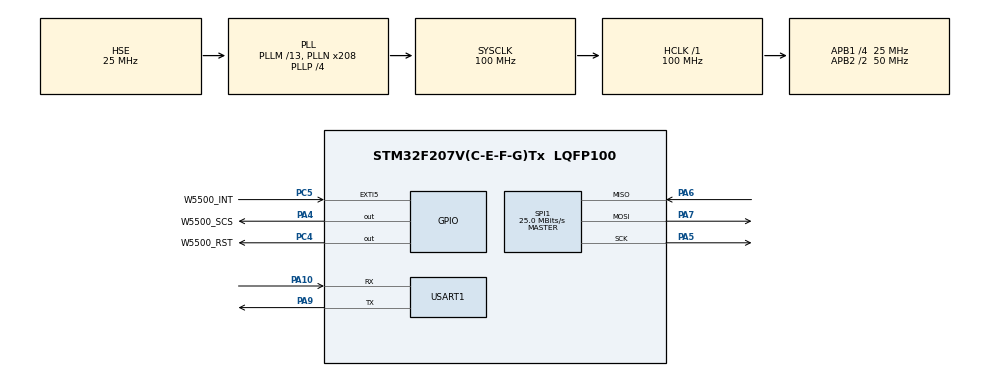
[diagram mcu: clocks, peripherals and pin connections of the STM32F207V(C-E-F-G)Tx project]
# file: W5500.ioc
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Mcu.Family=STM32F2
Mcu.Name=STM32F207V(C-E-F-G)Tx
Mcu.Package=LQFP100
NVIC.EXTI9_5_IRQn=true\:4\:0\:true\:true\:true\:1\:true
NVIC.PriorityGroup=NVIC_PRIORITYGROUP_4
PA10.Mode=Asynchronous
PA10.Signal=USART1_RX
PA13.Mode=Serial_Wire
PA13.Signal=SYS_JTMS-SWDIO
PA14.Mode=Serial_Wire
PA14.Signal=SYS_JTCK-SWCLK
PA4.GPIO_Label=W5500_SCS
PA4.Signal=GPIO_Output
PA5.Mode=Full_Duplex_Master
PA5.Signal=SPI1_SCK
PA6.Mode=Full_Duplex_Master
PA6.Signal=SPI1_MISO
PA7.Mode=Full_Duplex_Master
PA7.Signal=SPI1_MOSI
PA9.Mode=Asynchronous
PA9.Signal=USART1_TX
PC4.GPIO_Label=W5500_RST
PC4.Signal=GPIO_Output
PC5.GPIO_Label=W5500_INT
PC5.Signal=GPXTI5
PH0-OSC_IN.Mode=HSE-External-Oscillator
PH0-OSC_IN.Signal=RCC_OSC_IN
PH1-OSC_OUT.Mode=HSE-External-Oscillator
PH1-OSC_OUT.Signal=RCC_OSC_OUT
ProjectManager.HeapSize=0x200
ProjectManager.StackSize=0x400
ProjectManager.TargetToolchain=MDK-ARM V5
RCC.48MHZClocksFreq_Value=100000000
RCC.AHBFreq_Value=100000000
RCC.APB1CLKDivider=RCC_HCLK_DIV4
RCC.APB1Freq_Value=25000000
RCC.APB1TimFreq_Value=50000000
RCC.APB2CLKDivider=RCC_HCLK_DIV2
RCC.APB2Freq_Value=50000000
RCC.APB2TimFreq_Value=100000000
RCC.CortexFreq_Value=100000000
RCC.HCLKFreq_Value=100000000
RCC.HSE_VALUE=25000000
RCC.HSI_VALUE=16000000
RCC.LSE_VALUE=32768
RCC.PLLM=13
RCC.PLLN=208
RCC.PLLP=RCC_PLLP_DIV4
RCC.PLLSourceVirtual=RCC_PLLSOURCE_HSE
RCC.SYSCLKFreq_VALUE=100000000
RCC.SYSCLKSource=RCC_SYSCLKSOURCE_PLLCLK
RCC.VCOOutputFreq_Value=400000000
SPI1.BaudRatePrescaler=SPI_BAUDRATEPRESCALER_2
SPI1.CalculateBaudRate=25.0 MBits/s
SPI1.Direction=SPI_DIRECTION_2LINES
SPI1.Mode=SPI_MODE_MASTER
SPI1.VirtualType=VM_MASTER
USART1.VirtualMode=VM_ASYNC
board=W5500

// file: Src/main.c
/**
  ******************************************************************************
  * File Name          : main.c
  * Description        : Main program body
  ******************************************************************************
  ** This notice applies to any and all portions of this file
  * that are not between comment pairs USER CODE BEGIN and
  * USER CODE END. Other portions of this file, whether
  * inserted by the user or by software development tools
  * are owned by their respective copyright owners.
  *
  * COPYRIGHT(c) 2018 STMicroelectronics
  *
  * Redistribution and use in source and binary forms, with or without modification,
  * are permitted provided that the following conditions are met:
  *   1. Redistributions of source code must retain the above copyright notice,
  *      this list of conditions and the following disclaimer.
  *   2. Redistributions in binary form must reproduce the above copyright notice,
  *      this list of conditions and the following disclaimer in the documentation
  *      and/or other materials provided with the distribution.
  *   3. Neither the name of STMicroelectronics nor the names of its contributors
  *      may be used to endorse or promote products derived from this software
  *      without specific prior written permission.
  *
  * THIS SOFTWARE IS PROVIDED BY THE COPYRIGHT HOLDERS AND CONTRIBUTORS "AS IS"
  * AND ANY EXPRESS OR IMPLIED WARRANTIES, INCLUDING, BUT NOT LIMITED TO, THE
  * IMPLIED WARRANTIES OF MERCHANTABILITY AND FITNESS FOR A PARTICULAR PURPOSE ARE
  * DISCLAIMED. IN NO EVENT SHALL THE COPYRIGHT HOLDER OR CONTRIBUTORS BE LIABLE
  * FOR ANY DIRECT, INDIRECT, INCIDENTAL, SPECIAL, EXEMPLARY, OR CONSEQUENTIAL
  * DAMAGES (INCLUDING, BUT NOT LIMITED TO, PROCUREMENT OF SUBSTITUTE GOODS OR
  * SERVICES; LOSS OF USE, DATA, OR PROFITS; OR BUSINESS INTERRUPTION) HOWEVER
  * CAUSED AND ON ANY THEORY OF LIABILITY, WHETHER IN CONTRACT, STRICT LIABILITY,
  * OR TORT (INCLUDING NEGLIGENCE OR OTHERWISE) ARISING IN ANY WAY OUT OF THE USE
  * OF THIS SOFTWARE, EVEN IF ADVISED OF THE POSSIBILITY OF SUCH DAMAGE.
  *
  ******************************************************************************
  */

#include "main.h"
#include "stm32f2xx_hal.h"
#include "spi.h"
#include "usart.h"
#include "gpio.h"

/* USER CODE BEGIN Includes */
#include "Ethernet/W5500/w5500.h"
#include "Ethernet/W5500/w5500_conf.h"
#include "Ethernet/W5500/socket.h"
#include "Ethernet/W5500/utility.h"
#include "Ethernet/Internet/dhcp.h"
/*app函数头文件*/
#include "Ethernet/Internet/tcp_demo.h"

/* USER CODE END Includes */

/* USER CODE BEGIN PV */
#ifdef __GNUC__
  /* With GCC/RAISONANCE, small printf (option LD Linker->Libraries->Small printf
     set to 'Yes') calls __io_putchar() */
  #define PUTCHAR_PROTOTYPE int __io_putchar(int ch)
#else
  #define PUTCHAR_PROTOTYPE int fputc(int ch, FILE *f)
#endif /* __GNUC__ */

 /**
  * @brief  Retargets the C library printf function to the USART.
  * @param  None
  * @retval None
  */
PUTCHAR_PROTOTYPE
{
  /* Place your implementation of fputc here */
  /* e.g. write a character to the USART */
  HAL_UART_Transmit(&huart1, (uint8_t *)&ch, 1, 0xFFFF);
  return ch;
}

/* Private variables ---------------------------------------------------------*/

/* USER CODE END PV */

void SystemClock_Config(void);
static void MX_NVIC_Init(void);

/* USER CODE BEGIN PFP */
/* Private function prototypes -----------------------------------------------*/

/* USER CODE END PFP */

int main(void)
{

  /* MCU Configuration----------------------------------------------------------*/

  /* Reset of all peripherals, Initializes the Flash interface and the Systick. */
  HAL_Init();

  /* Configure the system clock */
  SystemClock_Config();

  /* Initialize all configured peripherals */
  MX_GPIO_Init();

  MX_USART1_UART_Init();

  MX_SPI1_Init();

  Systick_Init(100);

  /* Initialize interrupts */
//  MX_NVIC_Init();

   reset_w5500();                     /* W5500硬件复位 */
//   HAL_Delay(5000);
   printf("verson: %d\r\n", IINCHIP_READ(VERSIONR)); ///verson==4 则SPI正常 0x003900而不是0x0039否则读取失败
	/***** W5500的IP信息初始化 *****/

 #if    0  ///静态IP

	set_default(); 		///设置默认参数：MAC IP 网关 子网掩码												// 设置默认MAC、IP、GW、SUB、DNS
	set_network();
    printf("TCP Server IP: %d.%d.%d.%d \r\n",server_ip[0],server_ip[1],server_ip[2],server_ip[3]);
    printf("TCP Server Port: %d \r\n",server_port);
	printf("W5500 Init Complete!\r\n");
    printf("Start TCP Client Test!\r\n");

#else  //动态IP

   set_w5500_mac();
   init_dhcp_client();

   uint32_t timeover = HAL_GetTick();
   do_dhcp_ip( );

   printf("W5500 Init Complete! %d\r\n",HAL_GetTick()-timeover);
   timeover = 0;
   printf("Start DHCP Test!\r\n");

 #endif

    while(1) 														/*循环执行的函数*/
	{
        do_tcp_client(  );
	}
  /* USER CODE END 3 */

}

/** System Clock Configuration
*/
void SystemClock_Config(void)
{

  RCC_OscInitTypeDef RCC_OscInitStruct;
  RCC_ClkInitTypeDef RCC_ClkInitStruct;

    /**Initializes the CPU, AHB and APB busses clocks
    */
  RCC_OscInitStruct.OscillatorType = RCC_OSCILLATORTYPE_HSE;
  RCC_OscInitStruct.HSEState = RCC_HSE_ON;
  RCC_OscInitStruct.PLL.PLLState = RCC_PLL_ON;
  RCC_OscInitStruct.PLL.PLLSource = RCC_PLLSOURCE_HSE;
  RCC_OscInitStruct.PLL.PLLM = 13;
  RCC_OscInitStruct.PLL.PLLN = 208;
  RCC_OscInitStruct.PLL.PLLP = RCC_PLLP_DIV4;
  RCC_OscInitStruct.PLL.PLLQ = 4;
  if (HAL_RCC_OscConfig(&RCC_OscInitStruct) != HAL_OK)
  {
    _Error_Handler(__FILE__, __LINE__);
  }

    /**Initializes the CPU, AHB and APB busses clocks
    */
  RCC_ClkInitStruct.ClockType = RCC_CLOCKTYPE_HCLK|RCC_CLOCKTYPE_SYSCLK
                              |RCC_CLOCKTYPE_PCLK1|RCC_CLOCKTYPE_PCLK2;
  RCC_ClkInitStruct.SYSCLKSource = RCC_SYSCLKSOURCE_PLLCLK;
  RCC_ClkInitStruct.AHBCLKDivider = RCC_SYSCLK_DIV1;
  RCC_ClkInitStruct.APB1CLKDivider = RCC_HCLK_DIV4;
  RCC_ClkInitStruct.APB2CLKDivider = RCC_HCLK_DIV2;

  if (HAL_RCC_ClockConfig(&RCC_ClkInitStruct, FLASH_LATENCY_3) != HAL_OK)
  {
    _Error_Handler(__FILE__, __LINE__);
  }

    /**Configure the Systick interrupt time
    */
  HAL_SYSTICK_Config(HAL_RCC_GetHCLKFreq()/1000);

    /**Configure the Systick
    */
  HAL_SYSTICK_CLKSourceConfig(SYSTICK_CLKSOURCE_HCLK);

  /* SysTick_IRQn interrupt configuration */
  HAL_NVIC_SetPriority(SysTick_IRQn, 0, 0);
}

/** NVIC Configuration
*/
static void MX_NVIC_Init(void)
{
  /* EXTI9_5_IRQn interrupt configuration */
  HAL_NVIC_SetPriority(EXTI9_5_IRQn, 4, 0);
  HAL_NVIC_EnableIRQ(EXTI9_5_IRQn);
}

void _Error_Handler(char * file, int line)
{
  while(1)
  {
  }
}

/************************ (C) COPYRIGHT STMicroelectronics *****END OF FILE****/
